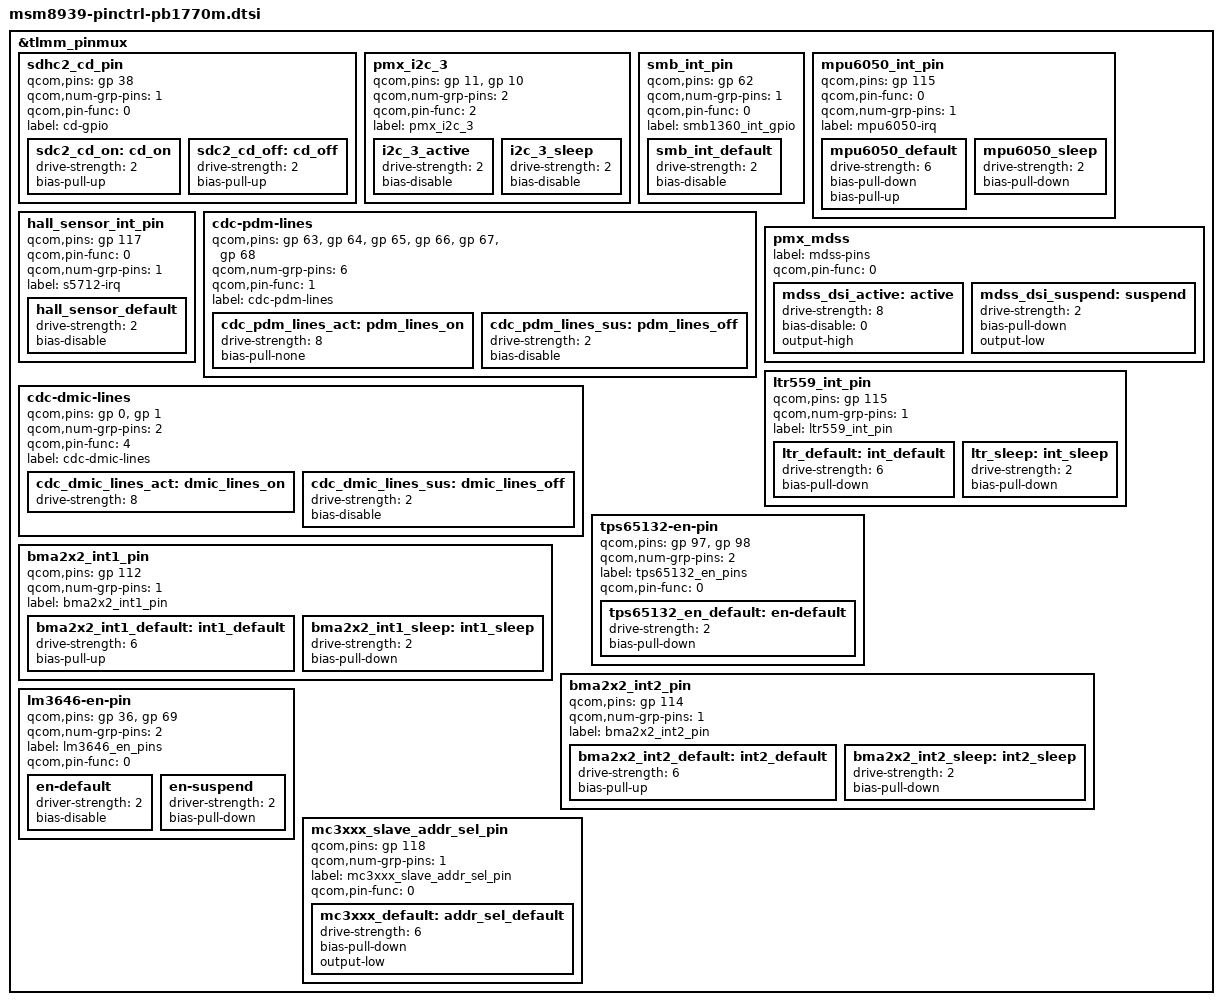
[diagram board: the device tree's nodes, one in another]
/* Copyright (c) 2020, The Linux Foundation. All rights reserved.
*  Copyright (c) 2015, Lenovo.
*  Copyright (c) 2020, the_shahnawaz_sheikh (sheikhshahnawaz41299).
*
* This program is free software; you can redistribute it and/or modify
* it under the terms of the GNU General Public License version 2 and
* only version 2 as published by the Free Software Foundation.
*
* This program is distributed in the hope that it will be useful,
* but WITHOUT ANY WARRANTY; without even the implied warranty of
* MERCHANTABILITY or FITNESS FOR A PARTICULAR PURPOSE.  See the
* GNU General Public License for more details.
*/

&tlmm_pinmux {
	
	/delete-node/ cdc-ext-spk-pa;
	/delete-node/ spi0_active;
	/delete-node/ spi0_suspend;
	/delete-node/ spi0_cs0_active;
	/delete-node/ spi0_cs0_suspend;
	/delete-node/ mod_en_active;
	/delete-node/ mod_en_suspend;
	/delete-node/ ddic_rst_active;
	/delete-node/ ddic_rst_suspend;
	
	sdhc2_cd_pin {
			qcom,pins = <&gp 38>;
			qcom,num-grp-pins = <1>;
			qcom,pin-func = <0>;
			label = "cd-gpio";
			sdc2_cd_on: cd_on {
				drive-strength = <2>;
				bias-pull-up;
			};
			sdc2_cd_off: cd_off {
				drive-strength = <2>;
				/delete-property/ bias-disable;
				bias-pull-up;
			};
		};
		
		pmx_i2c_3 {
			/* CLK, DATA */
			qcom,pins = <&gp 11>, <&gp 10>;
			qcom,num-grp-pins = <2>;
			qcom,pin-func = <2>;
			label = "pmx_i2c_3";

			i2c_3_active: i2c_3_active {
				drive-strength = <2>; /* 2 MA */
				bias-disable;         /* No PULL */
			};

			i2c_3_sleep: i2c_3_sleep {
				drive-strength = <2>; /* 2 MA */
				bias-disable;	      /* No PULL */
			};
		};
		
		smb_int_pin {
			qcom,pins = <&gp 62>;
			qcom,num-grp-pins = <1>;
			qcom,pin-func = <0>;
			label = "smb1360_int_gpio";
			smb_int_default: smb_int_default {
				drive-strength = <2>;	/* 2 MA */
				/delete-property/ bias-pull-up;
				bias-disable;
			};
		};
		
		mpu6050_int_pin {
			/* Gyroscope and accelerometer sensor combo */
			qcom,pins = <&gp 115>;
			qcom,pin-func = <0>;
			qcom,num-grp-pins = <1>;
			label = "mpu6050-irq";
			mpu6050_default: mpu6050_default {
				drive-strength = <6>;
				/delete-property/ bias-pull-up;
				bias-pull-down;
			};
			mpu6050_sleep: mpu6050_sleep {
				drive-strength = <2>;
				bias-pull-down;
			};
		};
			
		hall_sensor_int_pin {
			qcom,pins = <&gp 117>;
			qcom,pin-func = <0>;
			qcom,num-grp-pins = <1>;
			label = "s5712-irq";
			hall_sensor_default: hall_sensor_default {
				drive-strength = <2>;
				//bias-pull-up;
				bias-disable; 
			};
		};
		
		cdc-pdm-lines {
			qcom,pins = <&gp 63>, <&gp 64>, <&gp 65>,
					<&gp 66>, <&gp 67>, <&gp 68>;
			qcom,num-grp-pins = <6>;
			qcom,pin-func = <1>;
			label = "cdc-pdm-lines";
			cdc_pdm_lines_act: pdm_lines_on {
				drive-strength = <8>;
				bias-pull-none;
			};
			cdc_pdm_lines_sus: pdm_lines_off {
				drive-strength = <2>;
				/delete-property/ bias-pull-down;
				bias-disable;
			};
		};
		
		cdc-dmic-lines {
			qcom,pins = <&gp 0>, <&gp 1>;
			qcom,num-grp-pins = <2>;
			qcom,pin-func = <4>;
			label = "cdc-dmic-lines";
			cdc_dmic_lines_act: dmic_lines_on {
				drive-strength = <8>;
			};
			cdc_dmic_lines_sus: dmic_lines_off {
				drive-strength = <2>;
				bias-disable;
			};
		};
		
		pmx_mdss: pmx_mdss {
			label = "mdss-pins";
			qcom,pin-func = <0>;

			mdss_dsi_active: active {
				drive-strength = <8>; /* 8 mA */
				bias-disable = <0>; /* no pull */
				output-high;
			};
			mdss_dsi_suspend: suspend {
				drive-strength = <2>; /* 2 mA */
				bias-pull-down; /* pull down */
				output-low;
			};
		};
		
		ltr559_int_pin {
		qcom,pins = <&gp 115>;
		qcom,num-grp-pins = <1>;
		label = "ltr559_int_pin";
		ltr_default: int_default {
			  drive-strength = <6>;
			  bias-pull-down;
		};
		ltr_sleep: int_sleep {
			  drive-strength = <2>;
			  bias-pull-down;
		};
	};

	tps65132-en-pin {
		qcom,pins = <&gp 97>, <&gp 98>;
		qcom,num-grp-pins = <2>;
		label = "tps65132_en_pins";
		qcom,pin-func = <0>;

		tps65132_en_default: en-default {
			drive-strength = <2>;
			bias-pull-down;
		};
	};
	
	bma2x2_int1_pin {
		qcom,pins = <&gp 112>;
		qcom,num-grp-pins = <1>;
		label = "bma2x2_int1_pin";
		bma2x2_int1_default: int1_default {
			  drive-strength = <6>;
			  bias-pull-up;
		};
		bma2x2_int1_sleep: int1_sleep {
			  drive-strength = <2>;
			  bias-pull-down;
		};
	};

	bma2x2_int2_pin {
		qcom,pins = <&gp 114>;
		qcom,num-grp-pins = <1>;
		label = "bma2x2_int2_pin";
		bma2x2_int2_default: int2_default {
			  drive-strength = <6>;
			  bias-pull-up;
		};
		bma2x2_int2_sleep: int2_sleep {
			  drive-strength = <2>;
			  bias-pull-down;
		};
	};
	
	mpu6050_int_pin {
			/* Gyroscope and accelerometer sensor combo */
			qcom,pins = <&gp 115>;
			qcom,pin-func = <0>;
			qcom,num-grp-pins = <1>;
			label = "mpu6050-irq";
			mpu6050_default: mpu6050_default {
				drive-strength = <6>;
				bias-pull-up;
			};
			mpu6050_sleep: mpu6050_sleep {
				drive-strength = <2>;
				bias-pull-down;
			};
		};
		
	lm3646-en-pin {
				qcom,pins = <&gp 36>, <&gp 69>;
				qcom,num-grp-pins = <2>;
				label = "lm3646_en_pins";
				qcom,pin-func = <0>;

				en-default {
					driver-strength = <2>;
					bias-disable;
				};

				en-suspend {
					driver-strength = <2>;
					bias-pull-down;
				};
			};
			
		mc3xxx_slave_addr_sel_pin {
				qcom,pins = <&gp 118>;
				qcom,num-grp-pins = <1>;
				label = "mc3xxx_slave_addr_sel_pin";
				qcom,pin-func = <0>;

			mc3xxx_default:	addr_sel_default {
					drive-strength = <6>;
					bias-pull-down;
					output-low;
				};
			};
		
         
};
